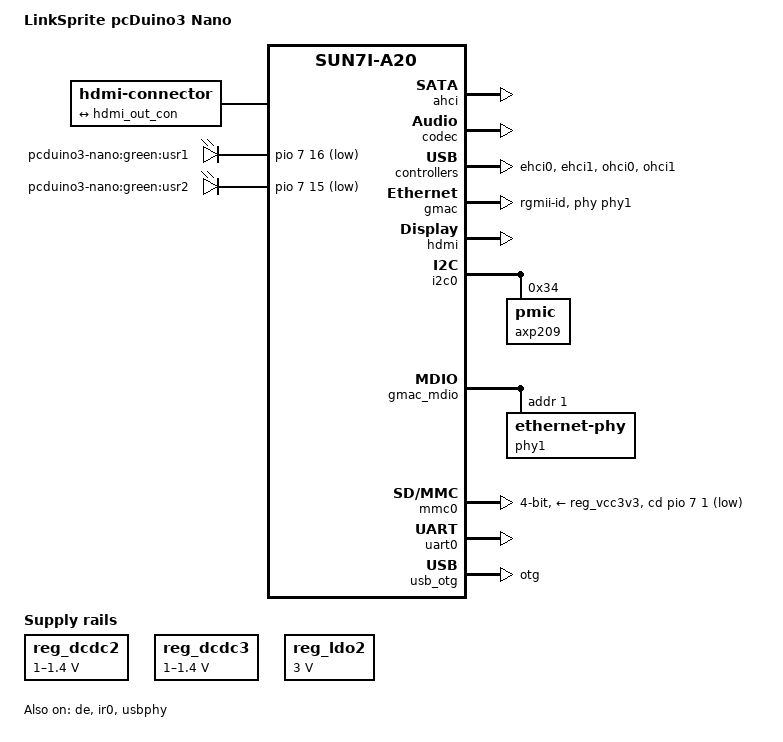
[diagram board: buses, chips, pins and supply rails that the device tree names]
/dts-v1/;
#include "sun7i-a20.dtsi"
#include "sunxi-common-regulators.dtsi"
#include <dt-bindings/gpio/gpio.h>
#include <dt-bindings/interrupt-controller/arm-gic.h>
/ {
	model = "LinkSprite pcDuino3 Nano";
	compatible = "linksprite,pcduino3-nano", "allwinner,sun7i-a20";
	aliases {
		serial0 = &uart0;
	};
	chosen {
		stdout-path = "serial0:115200n8";
	};
	hdmi-connector {
		compatible = "hdmi-connector";
		type = "a";
		port {
			hdmi_con_in: endpoint {
				remote-endpoint = <&hdmi_out_con>;
			};
		};
	};
	leds {
		compatible = "gpio-leds";
		led-3 {
			label = "pcduino3-nano:green:usr1";
			gpios = <&pio 7 16 GPIO_ACTIVE_LOW>;  
		};
		led-4 {
			label = "pcduino3-nano:green:usr2";
			gpios = <&pio 7 15 GPIO_ACTIVE_LOW>;  
		};
	};
};
&ahci {
	target-supply = <&reg_ahci_5v>;
	status = "okay";
};
&codec {
	status = "okay";
};
&cpu0 {
	cpu-supply = <&reg_dcdc2>;
};
&de {
	status = "okay";
};
&ehci0 {
	status = "okay";
};
&ehci1 {
	status = "okay";
};
&gmac {
	pinctrl-names = "default";
	pinctrl-0 = <&gmac_rgmii_pins>;
	phy-handle = <&phy1>;
	phy-mode = "rgmii-id";
	status = "okay";
};
&hdmi {
	status = "okay";
};
&hdmi_out {
	hdmi_out_con: endpoint {
		remote-endpoint = <&hdmi_con_in>;
	};
};
&i2c0 {
	status = "okay";
	axp209: pmic@34 {
		reg = <0x34>;
		interrupt-parent = <&nmi_intc>;
		interrupts = <0 IRQ_TYPE_LEVEL_LOW>;
	};
};
&ir0 {
	pinctrl-names = "default";
	pinctrl-0 = <&ir0_rx_pin>;
	status = "okay";
};
&gmac_mdio {
	phy1: ethernet-phy@1 {
		reg = <1>;
	};
};
&mmc0 {
	vmmc-supply = <&reg_vcc3v3>;
	bus-width = <4>;
	cd-gpios = <&pio 7 1 GPIO_ACTIVE_LOW>;  
	status = "okay";
};
&ohci0 {
	status = "okay";
};
&ohci1 {
	status = "okay";
};
&otg_sram {
	status = "okay";
};
&reg_ahci_5v {
	gpio = <&pio 7 2 GPIO_ACTIVE_HIGH>;  
	status = "okay";
};
#include "axp209.dtsi"
&reg_dcdc2 {
	regulator-always-on;
	regulator-min-microvolt = <1000000>;
	regulator-max-microvolt = <1400000>;
	regulator-name = "vdd-cpu";
};
&reg_dcdc3 {
	regulator-always-on;
	regulator-min-microvolt = <1000000>;
	regulator-max-microvolt = <1400000>;
	regulator-name = "vdd-int-pll";
};
&reg_ldo1 {
	regulator-name = "vdd-rtc";
};
&reg_ldo2 {
	regulator-always-on;
	regulator-min-microvolt = <3000000>;
	regulator-max-microvolt = <3000000>;
	regulator-name = "avcc";
};
&reg_usb1_vbus {
	gpio = <&pio 3 2 GPIO_ACTIVE_HIGH>;  
	status = "okay";
};
&uart0 {
	pinctrl-names = "default";
	pinctrl-0 = <&uart0_pb_pins>;
	status = "okay";
};
&usb_otg {
	dr_mode = "otg";
	status = "okay";
};
&usbphy {
	usb0_id_det-gpios = <&pio 7 4 (GPIO_ACTIVE_HIGH | GPIO_PULL_UP)>;  
	usb1_vbus-supply = <&reg_usb1_vbus>;
	usb2_vbus-supply = <&reg_usb1_vbus>;
	status = "okay";
};
